# RL6845_IP_SVD register map
Vendor: Realtek
IP svd file
Registers are 32-bit, read-write, reset 0x0 unless marked. A register's access mark holds for its fields unless they carry their own. Offsets are from the block's base; lines under a group give offsets from that group; [hi:lo] are bit positions; {n}, {i} and the like mark numbered series; 'fields as' and 'values as' point back to an identical list; <NAME> marks a mode.

## Memory map
0x00000000 PKE size 0x20
0x40000000 page0 size 0x100
0x40000000 page1 size 0x1200
0x40000000 page2 size 0x300
0x40000000 page3 size 0x1314
0x40000000 page4 size 0x1488
0x40000000 page5 size 0x15A4
0x40000000 page6 size 0x1700
0x40000000 page7 size 0x800
0x40100000 ipsec size 0x101C
0x40124000 spi size 0xB0C
0x40126000 psram_phy size 0xFC
0x40128000 spic size 0x1D4
0x4012A000 sport size 0x984
0x41000000 otpc size 0x44
0x41000000 otpc_sec size 0x744
0x41008000 lp_aon size 0x100
0x41008100 ldo size 0x80
0x41008180 swr size 0x80
0x41008200 lp_sys size 0x100
0x41008300 lp_pmc size 0x88
0x41008400 xtal size 0x3C
0x41008440 auxc size 0x40
0x41008480 wlafe size 0x40
0x41008600 memx size 0x200
0x41008800 pad size 0x200
0x41008A00 rtc size 0x2C
0x41008C00 iwdg size 0x14
0x41009000 sdm size 0x24
0x4100C000 uartirda size 0x64
0x4100F000 loguart size 0xF4
0x41010000 gpio size 0x100
0x41011000 adc size 0xBC
0x41011800 comp size 0x58
0x41012000 Cap-Touch size 0x214
0x41013000 kscan size 0x5C
0x41014000 ipc size 0x1C
0x41015000 debugtimer size 0x18
0x41016000 pmctimer size 0x34
0x41100000 timerpwm size 0x88
0x41101000 TRNG size 0x200
0x41102000 RXI-300 size 0x1140
0x41104000 RSIP size 0x300
0x41105000 ledc size 0xF8
0x41106000 audio size 0x82C
0x41107000 ir size 0x34
0x41108000 i2c size 0x104

## ipc
Base 0x41014000
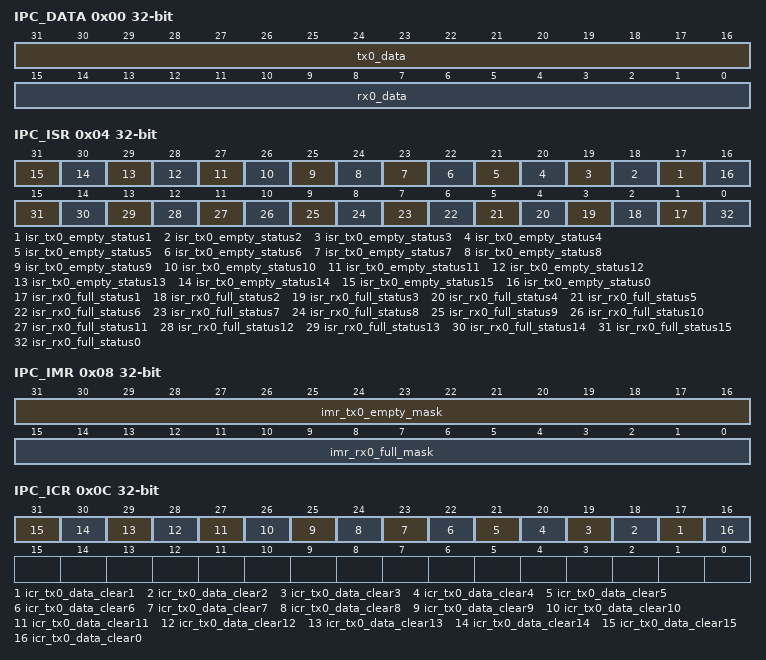
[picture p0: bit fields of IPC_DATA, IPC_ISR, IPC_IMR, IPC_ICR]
0x00 IPC_DATA access per field — Tx_Rx Register
  [31:16] tx0_data rw — After preparing descriptor, data and corresponding memory. 1: Writing 1 to the Tx data register (tx0_data) channel x bit, and the data will be mapped to the CPU0's RX data register (rx0_data) channel x bit. And the corresponding Rx full status bit in REG_ISR_CPU0 will be set. 0: Writing 0 has no effect. If the corresponding Rx full status bit in REG_ISR_CPU0 (e.g. isr_rx0_full_status6) is cleared, the corresponding bit in tx0_data will be cleaned automatically.
  [15:0] rx0_data ro — Rx data automatically maps data from tx0_data of CPU0
0x04 IPC_ISR ro — Interrupt Empty Full Status Register
  [n+16] isr_tx0_empty_status{n} (n=1..15) — Refer to the description of isr_tx0_empty_status0
  [16] isr_tx0_empty_status0 — Tx channel 0 empty interrupt status of CPU1 transmit to CPU0. If the corresponding Rx full status bit in REG_ISR_CPU0 (e.g. isr_rx0_full_status0) is cleared, the corresponding Tx empty status bit will be set automatically. It will be cleared by software writing 1.
  [n] isr_rx0_full_status{n} (n=1..15) — Refer to the description of isr_rx0_full_status0
  [0] isr_rx0_full_status0 — Rx channel 0 full interrupt status of CPU1. The corresponding Rx full status bit will be set by CPU0's Tx data register (tx0_data) channel 0. It will be cleared by software writing 1.
0x08 IPC_IMR — Interrupt Empty Full Mask Register
  [31:16] imr_tx0_empty_mask — 0: Mask Tx Channel x empty interrupt of CPU1 transmit to CPU0 1: Unmask Tx Channel x empty interrupt of CPU1 transmit to CPU0
  [15:0] imr_rx0_full_mask — 0: Mask Rx Channel x full interrupt of CPU1 received from CPU0 1: Unmask Rx Channel x full interrupt of CPU1 received from CPU0
0x0C IPC_ICR access per field — Clear Tx Register
  [n+16] icr_tx0_data_clear{n} ro (n=1..15) — Refer to the description of icr_tx0_data_clear0
  [16] icr_tx0_data_clear0 ro — 0: Writing 0 has no effect. 1: Clear the Tx data register (tx0_data) channel 0 bit.
0x10 IPC_SEM_0 ro
  [31:0] sem_0_data — Used to indicate who owns this semaphore .
0x14 IPC_SEM_1 ro
  [31:0] sem_1_data — Used to indicate who owns this semaphore .
0x18 IPC_DUMMY — Dummy Register
  [15:0] dummy

## sdm
Base 0x41009000
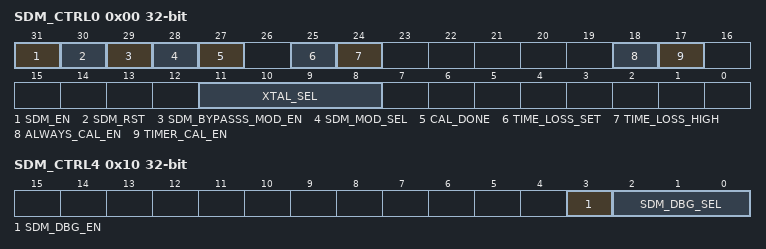
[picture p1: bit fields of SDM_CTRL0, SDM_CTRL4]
0x00 SDM_CTRL0 access per field — SDM Control Register
  [31] SDM_EN rw — Enable SDM
  [30] SDM_RST rw — 0: Reset SDM
  [29] SDM_BYPASSS_MOD_EN rw — Bypass mode enable
  [28] SDM_MOD_SEL rw — 0: Default mode 1: User-defined parameter mode
  [27] CAL_DONE ro
  [25] TIME_LOSS_SET rw — Time loss set 1: User-defined
  [24] TIME_LOSS_HIGH rw — Decide 32k output compensation direction 1: Mask 0: Add
  [18] ALWAYS_CAL_EN rw — 1: Enable always_cal
  [17] TIMER_CAL_EN rw — 1: Enable timer_cal
  [11:8] XTAL_SEL rw — XTAL frequency select, default 40M * 4'h0: XTAL40M * 4'h1: XTAL25M * 4'h4: XTAL20M * 4'h5: XTAL26M * 4'hD: XTAL27M * 4'hE: XTAL24M
0x04 SDM_CTRL1 — Config observed 128K cycle
  [15:0] SDM_OBS_CYC — Set observed 128k cycle, default 1024 128k cycles
0x08 SDM_CTRL2 — Set ref counter value
  [31:0] SDM_OBS_REF_CYC — Set in observed cycles, refer to counters value, default 312500 XTAL cycles
0x0C SDM_CTRL3 — Set XTAL period
  [31:0] XTAL_PERIOD — Set reference xtal period (ns)
0x10 SDM_CTRL4 — SDM Debug Register
  [3] SDM_DBG_EN — 1: Enable SDM debug
  [2:0] SDM_DBG_SEL — Set in observed cycles, refer to counters value
0x14 SDM_CTRL5 — Time loss Set
  [31:0] TIME_LOSS_REG — Source clock time loss every cycle
0x1C SDM_TIMEOUT reset 0x2000000 — Set Timer Trigger Counter Value
  [31:0] TIMEOUT_CNT — Set SDM timer trigger calibration timeout value
0x20 REG_SDM_DUMMY reset 0xFFFF — SDM Dummy Register

## Notices in the file
Copyright (C) 2012-2025 Realsil Limited. All rights reserved.
